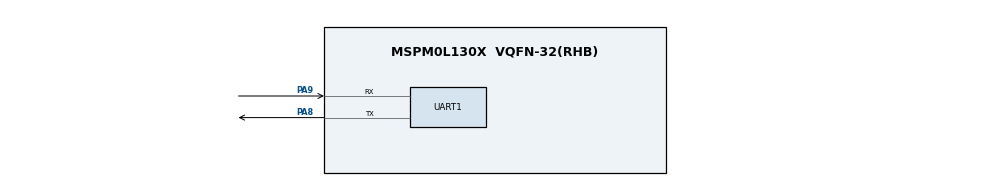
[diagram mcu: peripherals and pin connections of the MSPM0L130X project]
// @cliArgs --device "MSPM0L130X" --package "VQFN-32(RHB)" --part "Default"
// @cliArgs --board /ti/boards/LP_MSPM0L1306 --rtos nortos

/**
 * Import the modules used in this configuration.
 */
const UART   = scripting.addModule("/ti/driverlib/UART", {}, false);
const UART1  = UART.addInstance();

/**
 * Write custom configuration values to the imported modules.
 */

UART1.$name = "UART_0";
UART1.profile = "CONFIG_PROFILE_1";
UART1.peripheral.$assign = "UART0";
UART1.targetBaudRate = 9600;
UART1.enableInternalLoopback = false;
UART1.enabledInterrupts = ["DMA_DONE_RX"];
UART1.enableFIFO = true;
UART1.enabledDMARXTriggers = "DL_UART_DMA_INTERRUPT_RX";
UART1.enableDMARX          = true;

UART1.peripheral.txPin.$assign = "PA8";
UART1.peripheral.rxPin.$assign = "PA9";

UART1.DMA_CHANNEL_RX.peripheral.$assign = "DMA_CH0";
UART1.DMA_CHANNEL_RX.addressMode = "f2b";
UART1.DMA_CHANNEL_RX.dstIncDec = "INCREMENT";
UART1.DMA_CHANNEL_RX.dstLength = "BYTE";
UART1.DMA_CHANNEL_RX.srcLength = "BYTE";

const SYSCTL = scripting.addModule("/ti/driverlib/SYSCTL");
SYSCTL.clockTreeEn = true;
